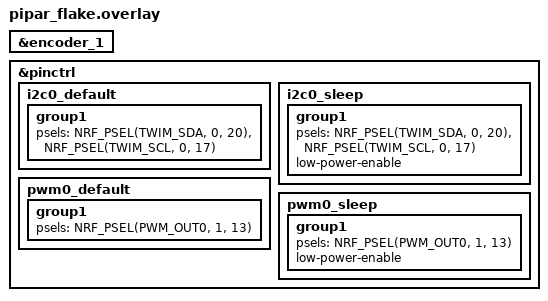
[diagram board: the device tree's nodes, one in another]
/*
 * Copyright (c) 2022 The ZMK Contributors
 *
 * SPDX-License-Identifier: MIT
 */

#include "pipar_flake.dtsi"

&encoder_1 {
    status = "okay";
};

&pinctrl {
    // swap the default sda and scl pins for the display to work.
    i2c0_default: i2c0_default {
            group1 {
                    psels = <NRF_PSEL(TWIM_SDA, 0, 20)>,
                            <NRF_PSEL(TWIM_SCL, 0, 17)>;
            };
    };

    i2c0_sleep: i2c0_sleep {
            group1 {
                    psels = <NRF_PSEL(TWIM_SDA, 0, 20)>,
                            <NRF_PSEL(TWIM_SCL, 0, 17)>;
                    low-power-enable;
            };
    };
    // Other pinctrl definitions for other hardware
    pwm0_default: pwm0_default {
        group1 {
            psels = <NRF_PSEL(PWM_OUT0, 1, 13)>;
        };
    };
    pwm0_sleep: pwm0_sleep {
        group1 {
            psels = <NRF_PSEL(PWM_OUT0, 1, 13)>;
            low-power-enable;
        };
    };
};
